AUTOSAR XML (schema 4-2-2)
package /STELLANTIS/EPT/SASWCs
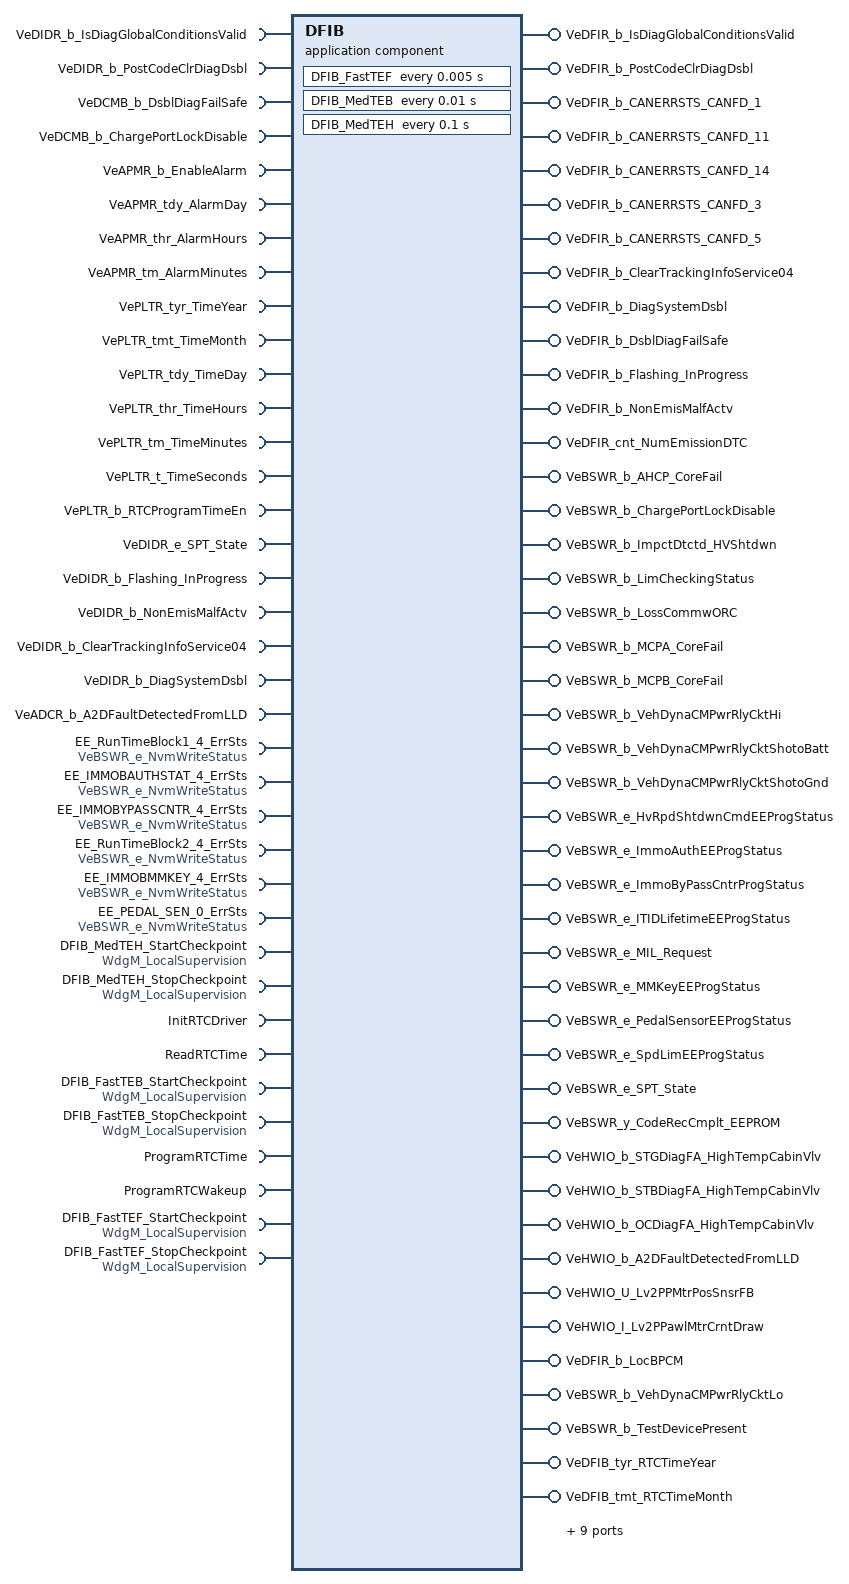
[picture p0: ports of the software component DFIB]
  application sw component type DFIB
    27 x require port:
      VeDIDR_b_IsDiagGlobalConditionsValid: nonqueued-receiver-com-spec{data-element=VeDIDR_b_IsDiagGlobalConditionsValid, init-value=0}, required-interface=VeDIDR_b_IsDiagGlobalConditionsValid
      VeDIDR_b_PostCodeClrDiagDsbl: nonqueued-receiver-com-spec{data-element=VeDIDR_b_PostCodeClrDiagDsbl, init-value=0}, required-interface=VeDIDR_b_PostCodeClrDiagDsbl
      VeDCMB_b_DsblDiagFailSafe: nonqueued-receiver-com-spec{data-element=VeDCMB_b_DsblDiagFailSafe, init-value=0}, required-interface=VeDCMB_b_DsblDiagFailSafe
      VeDCMB_b_ChargePortLockDisable: nonqueued-receiver-com-spec{data-element=VeDCMB_b_ChargePortLockDisable, init-value=0}, required-interface=VeDCMB_b_ChargePortLockDisable
      VeAPMR_b_EnableAlarm: nonqueued-receiver-com-spec{data-element=Value, init-value=0}, required-interface=VeAPMR_b_EnableAlarm
      VeAPMR_tdy_AlarmDay: nonqueued-receiver-com-spec{data-element=Value, init-value=0}, required-interface=VeAPMR_tdy_AlarmDay
      VeAPMR_thr_AlarmHours: nonqueued-receiver-com-spec{data-element=Value, init-value=0}, required-interface=VeAPMR_thr_AlarmHours
      VeAPMR_tm_AlarmMinutes: nonqueued-receiver-com-spec{data-element=Value, init-value=0}, required-interface=VeAPMR_tm_AlarmMinutes
      VePLTR_tyr_TimeYear: nonqueued-receiver-com-spec{data-element=Value, init-value=0}, required-interface=VePLTR_tyr_TimeYear
      VePLTR_tmt_TimeMonth: nonqueued-receiver-com-spec{data-element=Value, init-value=0}, required-interface=VePLTR_tmt_TimeMonth
      VePLTR_tdy_TimeDay: nonqueued-receiver-com-spec{data-element=Value, init-value=0}, required-interface=VePLTR_tdy_TimeDay
      VePLTR_thr_TimeHours: nonqueued-receiver-com-spec{data-element=Value, init-value=0}, required-interface=VePLTR_thr_TimeHours
      VePLTR_tm_TimeMinutes: nonqueued-receiver-com-spec{data-element=Value, init-value=0}, required-interface=VePLTR_tm_TimeMinutes
      VePLTR_t_TimeSeconds: nonqueued-receiver-com-spec{data-element=Value, init-value=0}, required-interface=VePLTR_t_TimeSeconds
      VePLTR_b_RTCProgramTimeEn: nonqueued-receiver-com-spec{data-element=Value, init-value=0}, required-interface=VePLTR_b_RTCProgramTimeEn
      VeDIDR_e_SPT_State: nonqueued-receiver-com-spec{data-element=VeDIDR_e_SPT_State, init-value=0}, required-interface=VeDIDR_e_SPT_State
      VeDIDR_b_Flashing_InProgress: nonqueued-receiver-com-spec{data-element=VeDIDR_b_Flashing_InProgress, init-value=0}, required-interface=VeDIDR_b_Flashing_InProgress
      VeDIDR_b_NonEmisMalfActv: nonqueued-receiver-com-spec{data-element=VeDIDR_b_NonEmisMalfActv, init-value=0}, required-interface=VeDIDR_b_NonEmisMalfActv
      VeDIDR_b_ClearTrackingInfoService04: nonqueued-receiver-com-spec{data-element=VeDIDR_b_ClearTrackingInfoService04, init-value=0}, required-interface=VeDIDR_b_ClearTrackingInfoService04
      VeDIDR_b_DiagSystemDsbl: nonqueued-receiver-com-spec{data-element=VeDIDR_b_DiagSystemDsbl, init-value=0}, required-interface=VeDIDR_b_DiagSystemDsbl
      VeADCR_b_A2DFaultDetectedFromLLD: nonqueued-receiver-com-spec{data-element=VeADCR_b_A2DFaultDetectedFromLLD, init-value=0}, required-interface=VeADCR_b_A2DFaultDetectedFromLLD
      EE_RunTimeBlock1_4_ErrSts: nonqueued-receiver-com-spec{data-element=VeBSWR_e_NvmWriteStatus, init-value=0}, required-interface=VeBSWR_e_NvmWriteStatus
      EE_IMMOBAUTHSTAT_4_ErrSts: nonqueued-receiver-com-spec{data-element=VeBSWR_e_NvmWriteStatus, init-value=0}, required-interface=VeBSWR_e_NvmWriteStatus
      EE_IMMOBYPASSCNTR_4_ErrSts: nonqueued-receiver-com-spec{data-element=VeBSWR_e_NvmWriteStatus, init-value=0}, required-interface=VeBSWR_e_NvmWriteStatus
      EE_RunTimeBlock2_4_ErrSts: nonqueued-receiver-com-spec{data-element=VeBSWR_e_NvmWriteStatus, init-value=0}, required-interface=VeBSWR_e_NvmWriteStatus
      EE_IMMOBMMKEY_4_ErrSts: nonqueued-receiver-com-spec{data-element=VeBSWR_e_NvmWriteStatus, init-value=0}, required-interface=VeBSWR_e_NvmWriteStatus
      EE_PEDAL_SEN_0_ErrSts: nonqueued-receiver-com-spec{data-element=VeBSWR_e_NvmWriteStatus, init-value=0}, required-interface=VeBSWR_e_NvmWriteStatus
    53 x provide port:
      VeDFIR_b_IsDiagGlobalConditionsValid: nonqueued-sender-com-spec{data-element=Value, init-value=0}, provided-interface=VeDFIR_b_IsDiagGlobalConditionsValid
      VeDFIR_b_PostCodeClrDiagDsbl: nonqueued-sender-com-spec{data-element=Value, init-value=0}, provided-interface=VeDFIR_b_PostCodeClrDiagDsbl
      VeDFIR_b_CANERRSTS_CANFD_1: nonqueued-sender-com-spec{data-element=Value, init-value=0}, provided-interface=VeDFIR_b_CANERRSTS_CANFD_1
      VeDFIR_b_CANERRSTS_CANFD_11: nonqueued-sender-com-spec{data-element=Value, init-value=0}, provided-interface=VeDFIR_b_CANERRSTS_CANFD_11
      VeDFIR_b_CANERRSTS_CANFD_14: nonqueued-sender-com-spec{data-element=Value, init-value=0}, provided-interface=VeDFIR_b_CANERRSTS_CANFD_14
      VeDFIR_b_CANERRSTS_CANFD_3: nonqueued-sender-com-spec{data-element=Value, init-value=0}, provided-interface=VeDFIR_b_CANERRSTS_CANFD_3
      VeDFIR_b_CANERRSTS_CANFD_5: nonqueued-sender-com-spec{data-element=Value, init-value=0}, provided-interface=VeDFIR_b_CANERRSTS_CANFD_5
      VeDFIR_b_ClearTrackingInfoService04: nonqueued-sender-com-spec{data-element=Value, init-value=0}, provided-interface=VeDFIR_b_ClearTrackingInfoService04
      VeDFIR_b_DiagSystemDsbl: nonqueued-sender-com-spec{data-element=Value, init-value=0}, provided-interface=VeDFIR_b_DiagSystemDsbl
      VeDFIR_b_DsblDiagFailSafe: nonqueued-sender-com-spec{data-element=Value, init-value=0}, provided-interface=VeDFIR_b_DsblDiagFailSafe
      VeDFIR_b_Flashing_InProgress: nonqueued-sender-com-spec{data-element=Value, init-value=0}, provided-interface=VeDFIR_b_Flashing_InProgress
      VeDFIR_b_NonEmisMalfActv: nonqueued-sender-com-spec{data-element=Value, init-value=0}, provided-interface=VeDFIR_b_NonEmisMalfActv
      VeDFIR_cnt_NumEmissionDTC: nonqueued-sender-com-spec{data-element=Value, init-value=0}, provided-interface=VeDFIR_cnt_NumEmissionDTC
      VeBSWR_b_AHCP_CoreFail: nonqueued-sender-com-spec{data-element=Value, init-value=0}, provided-interface=VeBSWR_b_AHCP_CoreFail
      VeBSWR_b_ChargePortLockDisable: nonqueued-sender-com-spec{data-element=Value, init-value=0}, provided-interface=VeBSWR_b_ChargePortLockDisable
      VeBSWR_b_ImpctDtctd_HVShtdwn: nonqueued-sender-com-spec{data-element=Value, init-value=0}, provided-interface=VeBSWR_b_ImpctDtctd_HVShtdwn
      VeBSWR_b_LimCheckingStatus: nonqueued-sender-com-spec{data-element=Value, init-value=0}, provided-interface=VeBSWR_b_LimCheckingStatus
      VeBSWR_b_LossCommwORC: nonqueued-sender-com-spec{data-element=Value, init-value=0}, provided-interface=VeBSWR_b_LossCommwORC
      VeBSWR_b_MCPA_CoreFail: nonqueued-sender-com-spec{data-element=Value, init-value=0}, provided-interface=VeBSWR_b_MCPA_CoreFail
      VeBSWR_b_MCPB_CoreFail: nonqueued-sender-com-spec{data-element=Value, init-value=0}, provided-interface=VeBSWR_b_MCPB_CoreFail
      VeBSWR_b_VehDynaCMPwrRlyCktHi: nonqueued-sender-com-spec{data-element=Value, init-value=0}, provided-interface=VeBSWR_b_VehDynaCMPwrRlyCktHi
      VeBSWR_b_VehDynaCMPwrRlyCktShotoBatt: nonqueued-sender-com-spec{data-element=Value, init-value=0}, provided-interface=VeBSWR_b_VehDynaCMPwrRlyCktShotoBatt
      VeBSWR_b_VehDynaCMPwrRlyCktShotoGnd: nonqueued-sender-com-spec{data-element=Value, init-value=0}, provided-interface=VeBSWR_b_VehDynaCMPwrRlyCktShotoGnd
      VeBSWR_e_HvRpdShtdwnCmdEEProgStatus: nonqueued-sender-com-spec{data-element=Value, init-value=0}, provided-interface=VeBSWR_e_HvRpdShtdwnCmdEEProgStatus
      VeBSWR_e_ImmoAuthEEProgStatus: nonqueued-sender-com-spec{data-element=Value, init-value=0}, provided-interface=VeBSWR_e_ImmoAuthEEProgStatus
      VeBSWR_e_ImmoByPassCntrProgStatus: nonqueued-sender-com-spec{data-element=Value, init-value=0}, provided-interface=VeBSWR_e_ImmoByPassCntrProgStatus
      VeBSWR_e_ITIDLifetimeEEProgStatus: nonqueued-sender-com-spec{data-element=Value, init-value=0}, provided-interface=VeBSWR_e_ITIDLifetimeEEProgStatus
      VeBSWR_e_MIL_Request: nonqueued-sender-com-spec{data-element=Value, init-value=CeDFIR_MIL_Off}, provided-interface=VeBSWR_e_MIL_Request
      VeBSWR_e_MMKeyEEProgStatus: nonqueued-sender-com-spec{data-element=Value, init-value=0}, provided-interface=VeBSWR_e_MMKeyEEProgStatus
      VeBSWR_e_PedalSensorEEProgStatus: nonqueued-sender-com-spec{data-element=Value, init-value=0}, provided-interface=VeBSWR_e_PedalSensorEEProgStatus
      VeBSWR_e_SpdLimEEProgStatus: nonqueued-sender-com-spec{data-element=Value, init-value=0}, provided-interface=VeBSWR_e_SpdLimEEProgStatus
      VeBSWR_e_SPT_State: nonqueued-sender-com-spec{data-element=Value, init-value=CeINVR_e_Pending_SPT}, provided-interface=VeBSWR_e_SPT_State
      VeBSWR_y_CodeRecCmplt_EEPROM: nonqueued-sender-com-spec{data-element=Value, init-value=0}, provided-interface=VeBSWR_y_CodeRecCmplt_EEPROM
      VeHWIO_b_STGDiagFA_HighTempCabinVlv: nonqueued-sender-com-spec{data-element=Value, init-value=0}, provided-interface=VeHWIO_b_STGDiagFA_HighTempCabinVlv
      VeHWIO_b_STBDiagFA_HighTempCabinVlv: nonqueued-sender-com-spec{data-element=Value, init-value=0}, provided-interface=VeHWIO_b_STBDiagFA_HighTempCabinVlv
      VeHWIO_b_OCDiagFA_HighTempCabinVlv: nonqueued-sender-com-spec{data-element=Value, init-value=0}, provided-interface=VeHWIO_b_OCDiagFA_HighTempCabinVlv
      VeHWIO_b_A2DFaultDetectedFromLLD: nonqueued-sender-com-spec{data-element=Value, init-value=0}, provided-interface=VeHWIO_b_A2DFaultDetectedFromLLD
      VeHWIO_U_Lv2PPMtrPosSnsrFB: nonqueued-sender-com-spec{data-element=Value, init-value=0}, provided-interface=VeHWIO_U_Lv2PPMtrPosSnsrFB
      VeHWIO_I_Lv2PPawlMtrCrntDraw: nonqueued-sender-com-spec{data-element=Value, init-value=0}, provided-interface=VeHWIO_I_Lv2PPawlMtrCrntDraw
      VeDFIR_b_LocBPCM: nonqueued-sender-com-spec{data-element=Value, init-value=0}, provided-interface=VeDFIR_b_LocBPCM
      VeBSWR_b_VehDynaCMPwrRlyCktLo: nonqueued-sender-com-spec{data-element=Value, init-value=0}, provided-interface=VeBSWR_b_VehDynaCMPwrRlyCktLo
      VeBSWR_b_TestDevicePresent: nonqueued-sender-com-spec{data-element=Value, init-value=0}, provided-interface=VeBSWR_b_TestDevicePresent
      VeDFIB_tyr_RTCTimeYear: nonqueued-sender-com-spec{data-element=Value, init-value=0}, provided-interface=VeDFIB_tyr_RTCTimeYear
      VeDFIB_tmt_RTCTimeMonth: nonqueued-sender-com-spec{data-element=Value, init-value=0}, provided-interface=VeDFIB_tmt_RTCTimeMonth
      VeDFIB_tdy_RTCTimeDay: nonqueued-sender-com-spec{data-element=Value, init-value=0}, provided-interface=VeDFIB_tdy_RTCTimeDay
      VeDFIB_thr_RTCTimeHour: nonqueued-sender-com-spec{data-element=Value, init-value=0}, provided-interface=VeDFIB_thr_RTCTimeHour
      VeDFIB_tmn_RTCTimeMinute: nonqueued-sender-com-spec{data-element=Value, init-value=0}, provided-interface=VeDFIB_tmn_RTCTimeMinute
      VeDFIB_t_RTCTimeSecond: nonqueued-sender-com-spec{data-element=Value, init-value=0}, provided-interface=VeDFIB_t_RTCTimeSecond
      VeDFIB_e_RTCReadSts: nonqueued-sender-com-spec{data-element=Value, init-value=CeDFIB_e_RTCCallInit}, provided-interface=VeDFIB_e_RTCReadSts
      VeDFIB_e_RTCWakeupReason: nonqueued-sender-com-spec{data-element=Value, init-value=CeDFIB_e_RTC_NO_WAKEUP}, provided-interface=VeDFIB_e_RTCWakeupReason
      VeDFIB_e_RTCProgramWakeupError: nonqueued-sender-com-spec{data-element=Value, init-value=CeDFIB_e_RTCCallInit}, provided-interface=VeDFIB_e_RTCProgramWakeupError
      VeDFIB_e_RTCProgramTimeSts: nonqueued-sender-com-spec{data-element=Value, init-value=CeDFIB_e_RTCCallInit}, provided-interface=VeDFIB_e_RTCProgramTimeSts
      VeDFIB_b_RTCChipErr: nonqueued-sender-com-spec{data-element=Value, init-value=0}, provided-interface=VeDFIB_b_RTCChipErr
    10 x require port:
      DFIB_MedTEH_StartCheckpoint: client-com-spec=CheckpointReached, required-interface=WdgM_LocalSupervision
      DFIB_MedTEH_StopCheckpoint: client-com-spec=CheckpointReached, required-interface=WdgM_LocalSupervision
      InitRTCDriver: client-com-spec=InitRTCDriver, required-interface=InitRTCDriver
      ReadRTCTime: client-com-spec=ReadRTCTime, required-interface=ReadRTCTime
      DFIB_FastTEB_StartCheckpoint: client-com-spec=CheckpointReached, required-interface=WdgM_LocalSupervision
      DFIB_FastTEB_StopCheckpoint: client-com-spec=CheckpointReached, required-interface=WdgM_LocalSupervision
      ProgramRTCTime: client-com-spec=ProgramRTCTime, required-interface=ProgramRTCTime
      ProgramRTCWakeup: client-com-spec=ProgramRTCWakeup, required-interface=ProgramRTCWakeup
      DFIB_FastTEF_StartCheckpoint: client-com-spec=CheckpointReached, required-interface=WdgM_LocalSupervision
      DFIB_FastTEF_StopCheckpoint: client-com-spec=CheckpointReached, required-interface=WdgM_LocalSupervision
    behavior IB_DFIB: data-type-mapping=[msADTtoIDTMapping, ADTtoIDTMapping], handle-termination-and-restart=NO-SUPPORT, included-data-type-set=data-type=TeDFIB_e_RTCErrors
      timing event Event_FastTEF: start-on-event=DFIB_FastTEF, period=0.005
      timing event Event_MedTEB: start-on-event=DFIB_MedTEB, period=0.01
      timing event Event_MedTEH: start-on-event=DFIB_MedTEH, period=0.1
      init event Event_DFIB_ac_Init: start-on-event=DFIB_ac_Init
      4 x runnable:
        DFIB_ac_Init
          data-send-points:
            7 x access:
              OUT_VeBSWR_e_MIL_Request_Value: accessed-variable=VeBSWR_e_MIL_Request.Value
              OUT_VeBSWR_e_SPT_State_Value: accessed-variable=VeBSWR_e_SPT_State.Value
              OUT_VeDFIB_tmt_RTCTimeMonth_Value: accessed-variable=VeDFIB_tmt_RTCTimeMonth.Value
              OUT_VeDFIB_tdy_RTCTimeDay_Value: accessed-variable=VeDFIB_tdy_RTCTimeDay.Value
              OUT_VeDFIB_e_RTCReadSts_Value: accessed-variable=VeDFIB_e_RTCReadSts.Value
              OUT_VeDFIB_e_RTCProgramWakeupError_Value: accessed-variable=VeDFIB_e_RTCProgramWakeupError.Value
              OUT_VeDFIB_e_RTCProgramTimeSts_Value: accessed-variable=VeDFIB_e_RTCProgramTimeSts.Value
        DFIB_FastTEF
          data-receive-point-by-arguments:
            16 x access:
              IN_EE_IMMOBAUTHSTAT_4_ErrSts_VeBSWR_e_NvmWriteStatus: accessed-variable=EE_IMMOBAUTHSTAT_4_ErrSts.VeBSWR_e_NvmWriteStatus
              IN_EE_IMMOBMMKEY_4_ErrSts_VeBSWR_e_NvmWriteStatus: accessed-variable=EE_IMMOBMMKEY_4_ErrSts.VeBSWR_e_NvmWriteStatus
              IN_EE_IMMOBYPASSCNTR_4_ErrSts_VeBSWR_e_NvmWriteStatus: accessed-variable=EE_IMMOBYPASSCNTR_4_ErrSts.VeBSWR_e_NvmWriteStatus
              IN_EE_PEDAL_SEN_0_ErrSts_VeBSWR_e_NvmWriteStatus: accessed-variable=EE_PEDAL_SEN_0_ErrSts.VeBSWR_e_NvmWriteStatus
              IN_EE_RunTimeBlock1_4_ErrSts_VeBSWR_e_NvmWriteStatus: accessed-variable=EE_RunTimeBlock1_4_ErrSts.VeBSWR_e_NvmWriteStatus
              IN_EE_RunTimeBlock2_4_ErrSts_VeBSWR_e_NvmWriteStatus: accessed-variable=EE_RunTimeBlock2_4_ErrSts.VeBSWR_e_NvmWriteStatus
              IN_VeADCR_b_A2DFaultDetectedFromLLD_VeADCR_b_A2DFaultDetectedFromLLD: accessed-variable=VeADCR_b_A2DFaultDetectedFromLLD.VeADCR_b_A2DFaultDetectedFromLLD
              IN_VeDCMB_b_ChargePortLockDisable_VeDCMB_b_ChargePortLockDisable: accessed-variable=VeDCMB_b_ChargePortLockDisable.VeDCMB_b_ChargePortLockDisable
              IN_VeDCMB_b_DsblDiagFailSafe_VeDCMB_b_DsblDiagFailSafe: accessed-variable=VeDCMB_b_DsblDiagFailSafe.VeDCMB_b_DsblDiagFailSafe
              IN_VeDIDR_b_ClearTrackingInfoService04_VeDIDR_b_ClearTrackingInfoService04: accessed-variable=VeDIDR_b_ClearTrackingInfoService04.VeDIDR_b_ClearTrackingInfoService04
              IN_VeDIDR_b_DiagSystemDsbl_VeDIDR_b_DiagSystemDsbl: accessed-variable=VeDIDR_b_DiagSystemDsbl.VeDIDR_b_DiagSystemDsbl
              IN_VeDIDR_b_Flashing_InProgress_VeDIDR_b_Flashing_InProgress: accessed-variable=VeDIDR_b_Flashing_InProgress.VeDIDR_b_Flashing_InProgress
              IN_VeDIDR_b_IsDiagGlobalConditionsValid_VeDIDR_b_IsDiagGlobalConditionsValid: accessed-variable=VeDIDR_b_IsDiagGlobalConditionsValid.VeDIDR_b_IsDiagGlobalConditionsValid
              IN_VeDIDR_b_NonEmisMalfActv_VeDIDR_b_NonEmisMalfActv: accessed-variable=VeDIDR_b_NonEmisMalfActv.VeDIDR_b_NonEmisMalfActv
              IN_VeDIDR_b_PostCodeClrDiagDsbl_VeDIDR_b_PostCodeClrDiagDsbl: accessed-variable=VeDIDR_b_PostCodeClrDiagDsbl.VeDIDR_b_PostCodeClrDiagDsbl
              IN_VeDIDR_e_SPT_State_VeDIDR_e_SPT_State: accessed-variable=VeDIDR_e_SPT_State.VeDIDR_e_SPT_State
          data-send-points:
            42 x access:
              OUT_VeDFIR_b_IsDiagGlobalConditionsValid_Value: accessed-variable=VeDFIR_b_IsDiagGlobalConditionsValid.Value
              OUT_VeDFIR_b_PostCodeClrDiagDsbl_Value: accessed-variable=VeDFIR_b_PostCodeClrDiagDsbl.Value
              OUT_VeDFIR_b_CANERRSTS_CANFD_1_Value: accessed-variable=VeDFIR_b_CANERRSTS_CANFD_1.Value
              OUT_VeDFIR_b_CANERRSTS_CANFD_11_Value: accessed-variable=VeDFIR_b_CANERRSTS_CANFD_11.Value
              OUT_VeDFIR_b_CANERRSTS_CANFD_14_Value: accessed-variable=VeDFIR_b_CANERRSTS_CANFD_14.Value
              OUT_VeDFIR_b_CANERRSTS_CANFD_3_Value: accessed-variable=VeDFIR_b_CANERRSTS_CANFD_3.Value
              OUT_VeDFIR_b_CANERRSTS_CANFD_5_Value: accessed-variable=VeDFIR_b_CANERRSTS_CANFD_5.Value
              OUT_VeDFIR_b_ClearTrackingInfoService04_Value: accessed-variable=VeDFIR_b_ClearTrackingInfoService04.Value
              OUT_VeDFIR_b_DiagSystemDsbl_Value: accessed-variable=VeDFIR_b_DiagSystemDsbl.Value
              OUT_VeDFIR_b_DsblDiagFailSafe_Value: accessed-variable=VeDFIR_b_DsblDiagFailSafe.Value
              OUT_VeDFIR_b_Flashing_InProgress_Value: accessed-variable=VeDFIR_b_Flashing_InProgress.Value
              OUT_VeDFIR_b_NonEmisMalfActv_Value: accessed-variable=VeDFIR_b_NonEmisMalfActv.Value
              OUT_VeDFIR_cnt_NumEmissionDTC_Value: accessed-variable=VeDFIR_cnt_NumEmissionDTC.Value
              OUT_VeBSWR_b_AHCP_CoreFail_Value: accessed-variable=VeBSWR_b_AHCP_CoreFail.Value
              OUT_VeBSWR_b_ChargePortLockDisable_Value: accessed-variable=VeBSWR_b_ChargePortLockDisable.Value
              OUT_VeBSWR_b_ImpctDtctd_HVShtdwn_Value: accessed-variable=VeBSWR_b_ImpctDtctd_HVShtdwn.Value
              OUT_VeBSWR_b_LimCheckingStatus_Value: accessed-variable=VeBSWR_b_LimCheckingStatus.Value
              OUT_VeBSWR_b_LossCommwORC_Value: accessed-variable=VeBSWR_b_LossCommwORC.Value
              OUT_VeBSWR_b_MCPA_CoreFail_Value: accessed-variable=VeBSWR_b_MCPA_CoreFail.Value
              OUT_VeBSWR_b_MCPB_CoreFail_Value: accessed-variable=VeBSWR_b_MCPB_CoreFail.Value
              OUT_VeBSWR_b_VehDynaCMPwrRlyCktHi_Value: accessed-variable=VeBSWR_b_VehDynaCMPwrRlyCktHi.Value
              OUT_VeBSWR_b_VehDynaCMPwrRlyCktShotoBatt_Value: accessed-variable=VeBSWR_b_VehDynaCMPwrRlyCktShotoBatt.Value
              OUT_VeBSWR_b_VehDynaCMPwrRlyCktShotoGnd_Value: accessed-variable=VeBSWR_b_VehDynaCMPwrRlyCktShotoGnd.Value
              OUT_VeBSWR_e_HvRpdShtdwnCmdEEProgStatus_Value: accessed-variable=VeBSWR_e_HvRpdShtdwnCmdEEProgStatus.Value
              OUT_VeBSWR_e_ImmoAuthEEProgStatus_Value: accessed-variable=VeBSWR_e_ImmoAuthEEProgStatus.Value
              OUT_VeBSWR_e_ImmoByPassCntrProgStatus_Value: accessed-variable=VeBSWR_e_ImmoByPassCntrProgStatus.Value
              OUT_VeBSWR_e_ITIDLifetimeEEProgStatus_Value: accessed-variable=VeBSWR_e_ITIDLifetimeEEProgStatus.Value
              OUT_VeBSWR_e_MIL_Request_Value: accessed-variable=VeBSWR_e_MIL_Request.Value
              OUT_VeBSWR_e_MMKeyEEProgStatus_Value: accessed-variable=VeBSWR_e_MMKeyEEProgStatus.Value
              OUT_VeBSWR_e_PedalSensorEEProgStatus_Value: accessed-variable=VeBSWR_e_PedalSensorEEProgStatus.Value
              OUT_VeBSWR_e_SpdLimEEProgStatus_Value: accessed-variable=VeBSWR_e_SpdLimEEProgStatus.Value
              OUT_VeBSWR_e_SPT_State_Value: accessed-variable=VeBSWR_e_SPT_State.Value
              OUT_VeBSWR_y_CodeRecCmplt_EEPROM_Value: accessed-variable=VeBSWR_y_CodeRecCmplt_EEPROM.Value
              OUT_VeHWIO_b_STGDiagFA_HighTempCabinVlv_Value: accessed-variable=VeHWIO_b_STGDiagFA_HighTempCabinVlv.Value
              OUT_VeHWIO_b_STBDiagFA_HighTempCabinVlv_Value: accessed-variable=VeHWIO_b_STBDiagFA_HighTempCabinVlv.Value
              OUT_VeHWIO_b_OCDiagFA_HighTempCabinVlv_Value: accessed-variable=VeHWIO_b_OCDiagFA_HighTempCabinVlv.Value
              OUT_VeHWIO_b_A2DFaultDetectedFromLLD_Value: accessed-variable=VeHWIO_b_A2DFaultDetectedFromLLD.Value
              OUT_VeHWIO_U_Lv2PPMtrPosSnsrFB_Value: accessed-variable=VeHWIO_U_Lv2PPMtrPosSnsrFB.Value
              OUT_VeHWIO_I_Lv2PPawlMtrCrntDraw_Value: accessed-variable=VeHWIO_I_Lv2PPawlMtrCrntDraw.Value
              OUT_VeBSWR_b_VehDynaCMPwrRlyCktLo_Value: accessed-variable=VeBSWR_b_VehDynaCMPwrRlyCktLo.Value
              OUT_VeBSWR_b_TestDevicePresent_Value: accessed-variable=VeBSWR_b_TestDevicePresent.Value
              OUT_VeDFIR_b_LocBPCM_Value: accessed-variable=VeDFIR_b_LocBPCM.Value
          sync call SC_DFIB_FastTEF_StartCheckpoint_CheckpointReached: operation=DFIB_FastTEF_StartCheckpoint.CheckpointReached, timeout=1E-06
          sync call SC_DFIB_FastTEF_StopCheckpoint_CheckpointReached: operation=DFIB_FastTEF_StopCheckpoint.CheckpointReached, timeout=1E-06
        DFIB_MedTEB
          data-receive-point-by-arguments:
            11 x access:
              IN_VeAPMR_b_EnableAlarm_Value: accessed-variable=VeAPMR_b_EnableAlarm.Value
              IN_VeAPMR_tdy_AlarmDay_Value: accessed-variable=VeAPMR_tdy_AlarmDay.Value
              IN_VeAPMR_thr_AlarmHours_Value: accessed-variable=VeAPMR_thr_AlarmHours.Value
              IN_VeAPMR_tm_AlarmMinutes_Value: accessed-variable=VeAPMR_tm_AlarmMinutes.Value
              IN_VePLTR_b_RTCProgramTimeEn_Value: accessed-variable=VePLTR_b_RTCProgramTimeEn.Value
              IN_VePLTR_t_TimeSeconds_Value: accessed-variable=VePLTR_t_TimeSeconds.Value
              IN_VePLTR_tdy_TimeDay_Value: accessed-variable=VePLTR_tdy_TimeDay.Value
              IN_VePLTR_thr_TimeHours_Value: accessed-variable=VePLTR_thr_TimeHours.Value
              IN_VePLTR_tm_TimeMinutes_Value: accessed-variable=VePLTR_tm_TimeMinutes.Value
              IN_VePLTR_tmt_TimeMonth_Value: accessed-variable=VePLTR_tmt_TimeMonth.Value
              IN_VePLTR_tyr_TimeYear_Value: accessed-variable=VePLTR_tyr_TimeYear.Value
          data-send-points:
            access OUT_VeDFIB_e_RTCProgramWakeupError_Value: accessed-variable=VeDFIB_e_RTCProgramWakeupError.Value
            access OUT_VeDFIB_e_RTCProgramTimeSts_Value: accessed-variable=VeDFIB_e_RTCProgramTimeSts.Value
            access OUT_VeDFIB_b_RTCChipErr_Value: accessed-variable=VeDFIB_b_RTCChipErr.Value
          4 x sync call, all with timeout=1E-06:
            SC_DFIB_FastTEB_StartCheckpoint_CheckpointReached: operation=DFIB_FastTEB_StartCheckpoint.CheckpointReached
            SC_DFIB_FastTEB_StopCheckpoint_CheckpointReached: operation=DFIB_FastTEB_StopCheckpoint.CheckpointReached
            SC_ProgramRTCTime_ProgramRTCTime: operation=ProgramRTCTime.ProgramRTCTime
            SC_ProgramRTCWakeup_ProgramRTCWakeup: operation=ProgramRTCWakeup.ProgramRTCWakeup
        DFIB_MedTEH
          data-send-points:
            9 x access:
              OUT_VeDFIB_e_RTCWakeupReason_Value: accessed-variable=VeDFIB_e_RTCWakeupReason.Value
              OUT_VeDFIB_tyr_RTCTimeYear_Value: accessed-variable=VeDFIB_tyr_RTCTimeYear.Value
              OUT_VeDFIB_tmt_RTCTimeMonth_Value: accessed-variable=VeDFIB_tmt_RTCTimeMonth.Value
              OUT_VeDFIB_tdy_RTCTimeDay_Value: accessed-variable=VeDFIB_tdy_RTCTimeDay.Value
              OUT_VeDFIB_thr_RTCTimeHour_Value: accessed-variable=VeDFIB_thr_RTCTimeHour.Value
              OUT_VeDFIB_tmn_RTCTimeMinute_Value: accessed-variable=VeDFIB_tmn_RTCTimeMinute.Value
              OUT_VeDFIB_t_RTCTimeSecond_Value: accessed-variable=VeDFIB_t_RTCTimeSecond.Value
              OUT_VeDFIB_e_RTCReadSts_Value: accessed-variable=VeDFIB_e_RTCReadSts.Value
              OUT_VeDFIB_b_RTCChipErr_Value: accessed-variable=VeDFIB_b_RTCChipErr.Value
          4 x sync call, all with timeout=1E-06:
            SC_DFIB_MedTEH_StartCheckpoint_CheckpointReached: operation=DFIB_MedTEH_StartCheckpoint.CheckpointReached
            SC_DFIB_MedTEH_StopCheckpoint_CheckpointReached: operation=DFIB_MedTEH_StopCheckpoint.CheckpointReached
            SC_InitRTCDriver_InitRTCDriver: operation=InitRTCDriver.InitRTCDriver
            SC_ReadRTCTime_ReadRTCTime: operation=ReadRTCTime.ReadRTCTime
